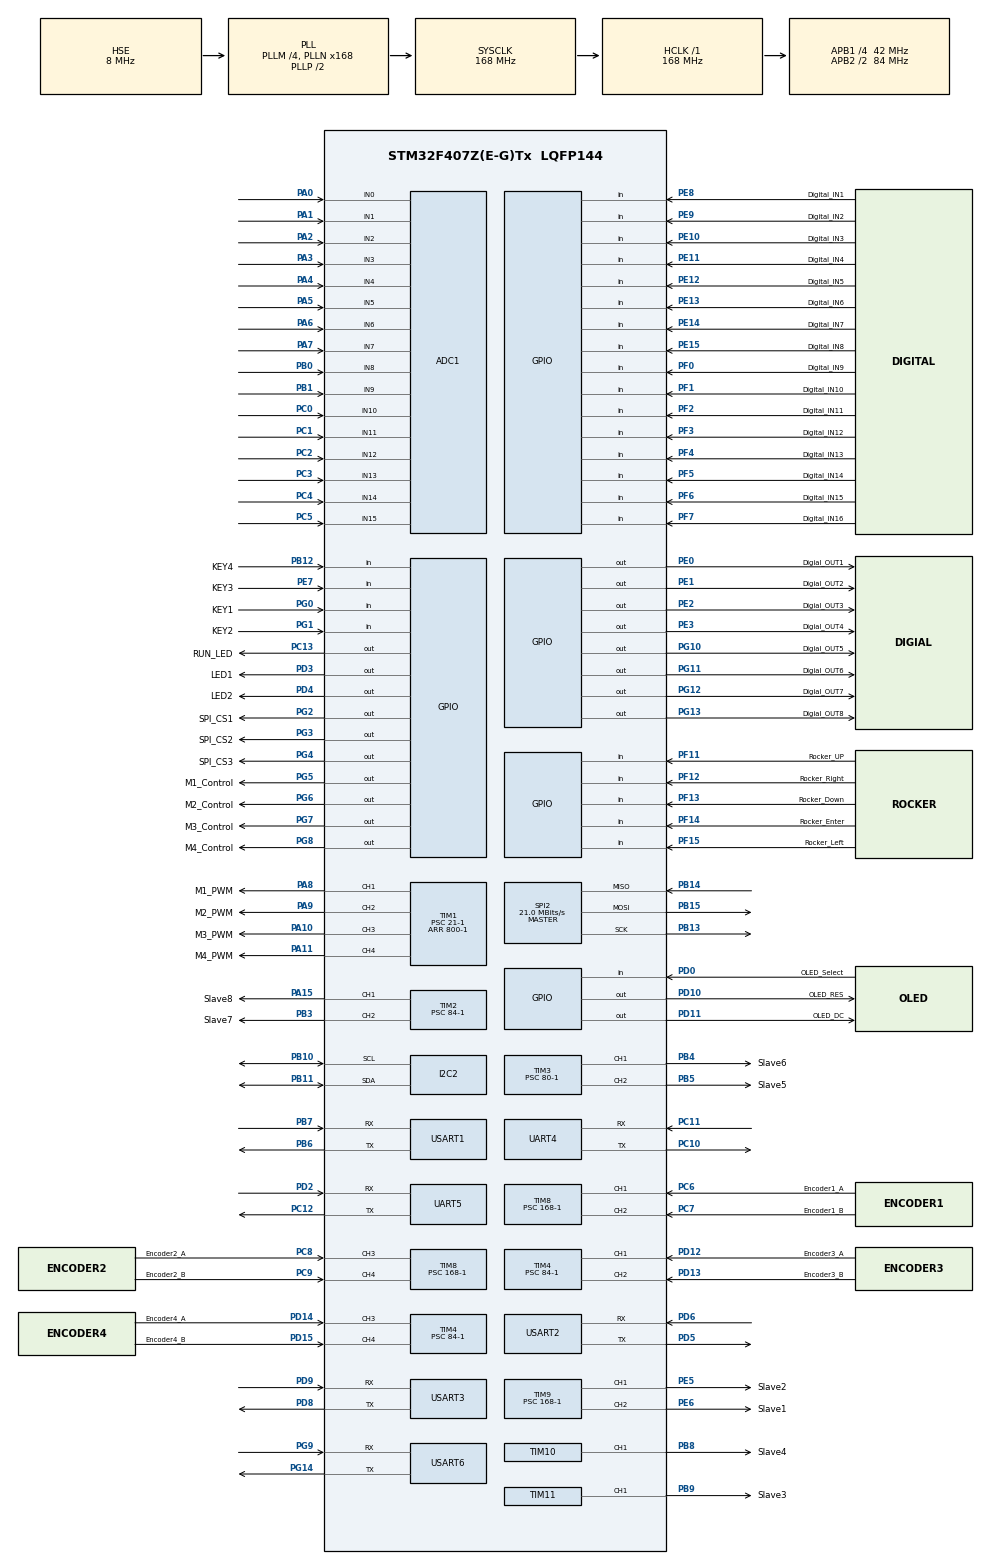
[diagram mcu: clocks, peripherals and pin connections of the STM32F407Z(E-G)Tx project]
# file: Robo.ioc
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ADC1.Channel-1\#ChannelRegularConversion=ADC_CHANNEL_0
ADC1.Channel-2\#ChannelRegularConversion=ADC_CHANNEL_2
ADC1.Channel-3\#ChannelRegularConversion=ADC_CHANNEL_4
ADC1.Channel-4\#ChannelRegularConversion=ADC_CHANNEL_6
ADC1.Channel-5\#ChannelRegularConversion=ADC_CHANNEL_8
ADC1.Channel-6\#ChannelRegularConversion=ADC_CHANNEL_10
ADC1.Channel-7\#ChannelRegularConversion=ADC_CHANNEL_12
ADC1.Channel-8\#ChannelRegularConversion=ADC_CHANNEL_14
ADC1.ClockPrescaler=ADC_CLOCK_SYNC_PCLK_DIV8
ADC1.DMAContinuousRequests=ENABLE
ADC1.ExternalTrigConv=ADC_EXTERNALTRIGCONV_T5_CC1
ADC1.Mode=ADC_DUALMODE_REGSIMULT
ADC1.NbrOfConversion=8
ADC1.NbrOfConversionFlag=1
ADC1.Rank-1\#ChannelRegularConversion=1
ADC1.Rank-2\#ChannelRegularConversion=2
ADC1.Rank-3\#ChannelRegularConversion=3
ADC1.Rank-4\#ChannelRegularConversion=4
ADC1.Rank-5\#ChannelRegularConversion=5
ADC1.Rank-6\#ChannelRegularConversion=6
ADC1.Rank-7\#ChannelRegularConversion=7
ADC1.Rank-8\#ChannelRegularConversion=8
ADC1.SamplingTime-1\#ChannelRegularConversion=ADC_SAMPLETIME_56CYCLES
ADC1.SamplingTime-2\#ChannelRegularConversion=ADC_SAMPLETIME_56CYCLES
ADC1.SamplingTime-3\#ChannelRegularConversion=ADC_SAMPLETIME_56CYCLES
ADC1.SamplingTime-4\#ChannelRegularConversion=ADC_SAMPLETIME_56CYCLES
ADC1.SamplingTime-5\#ChannelRegularConversion=ADC_SAMPLETIME_56CYCLES
ADC1.SamplingTime-6\#ChannelRegularConversion=ADC_SAMPLETIME_56CYCLES
ADC1.SamplingTime-7\#ChannelRegularConversion=ADC_SAMPLETIME_56CYCLES
ADC1.SamplingTime-8\#ChannelRegularConversion=ADC_SAMPLETIME_56CYCLES
ADC1.master=1
ADC2.Channel-0\#ChannelRegularConversion=ADC_CHANNEL_1
ADC2.Channel-1\#ChannelRegularConversion=ADC_CHANNEL_3
ADC2.Channel-2\#ChannelRegularConversion=ADC_CHANNEL_5
ADC2.Channel-3\#ChannelRegularConversion=ADC_CHANNEL_7
ADC2.Channel-4\#ChannelRegularConversion=ADC_CHANNEL_9
ADC2.Channel-5\#ChannelRegularConversion=ADC_CHANNEL_11
ADC2.Channel-6\#ChannelRegularConversion=ADC_CHANNEL_13
ADC2.Channel-7\#ChannelRegularConversion=ADC_CHANNEL_15
ADC2.ClockPrescaler=ADC_CLOCK_SYNC_PCLK_DIV8
ADC2.DMAAccessMode=ADC_DMAACCESSMODE_2
ADC2.Mode=ADC_DUALMODE_REGSIMULT
ADC2.NbrOfConversion=8
ADC2.NbrOfConversionFlag=1
ADC2.Rank-0\#ChannelRegularConversion=1
ADC2.Rank-1\#ChannelRegularConversion=2
ADC2.Rank-2\#ChannelRegularConversion=3
ADC2.Rank-3\#ChannelRegularConversion=4
ADC2.Rank-4\#ChannelRegularConversion=5
ADC2.Rank-5\#ChannelRegularConversion=6
ADC2.Rank-6\#ChannelRegularConversion=7
ADC2.Rank-7\#ChannelRegularConversion=8
ADC2.SamplingTime-0\#ChannelRegularConversion=ADC_SAMPLETIME_56CYCLES
ADC2.SamplingTime-1\#ChannelRegularConversion=ADC_SAMPLETIME_56CYCLES
ADC2.SamplingTime-2\#ChannelRegularConversion=ADC_SAMPLETIME_56CYCLES
ADC2.SamplingTime-3\#ChannelRegularConversion=ADC_SAMPLETIME_56CYCLES
ADC2.SamplingTime-4\#ChannelRegularConversion=ADC_SAMPLETIME_56CYCLES
ADC2.SamplingTime-5\#ChannelRegularConversion=ADC_SAMPLETIME_56CYCLES
ADC2.SamplingTime-6\#ChannelRegularConversion=ADC_SAMPLETIME_56CYCLES
ADC2.SamplingTime-7\#ChannelRegularConversion=ADC_SAMPLETIME_56CYCLES
Dma.ADC1.0.Direction=DMA_PERIPH_TO_MEMORY
Dma.ADC1.0.FIFOMode=DMA_FIFOMODE_DISABLE
Dma.ADC1.0.Instance=DMA2_Stream0
Dma.ADC1.0.MemDataAlignment=DMA_MDATAALIGN_WORD
Dma.ADC1.0.MemInc=DMA_MINC_ENABLE
Dma.ADC1.0.Mode=DMA_CIRCULAR
Dma.ADC1.0.PeriphDataAlignment=DMA_PDATAALIGN_WORD
Dma.ADC1.0.PeriphInc=DMA_PINC_DISABLE
Dma.ADC1.0.Priority=DMA_PRIORITY_MEDIUM
Dma.Request0=ADC1
Dma.Request1=TIM4_CH1
Dma.Request2=TIM8_CH1
Dma.Request3=TIM8_CH2
Dma.Request4=TIM8_CH3
Dma.Request5=TIM8_CH4/TRIG/COM
Dma.Request6=TIM4_CH2
Dma.Request7=TIM4_CH3
Dma.Request8=USART3_TX
Dma.Request9=USART3_RX
Dma.TIM4_CH1.1.Direction=DMA_PERIPH_TO_MEMORY
Dma.TIM4_CH1.1.FIFOMode=DMA_FIFOMODE_DISABLE
Dma.TIM4_CH1.1.Instance=DMA1_Stream0
Dma.TIM4_CH1.1.MemDataAlignment=DMA_MDATAALIGN_HALFWORD
Dma.TIM4_CH1.1.MemInc=DMA_MINC_DISABLE
Dma.TIM4_CH1.1.Mode=DMA_CIRCULAR
Dma.TIM4_CH1.1.PeriphDataAlignment=DMA_PDATAALIGN_HALFWORD
Dma.TIM4_CH1.1.PeriphInc=DMA_PINC_DISABLE
Dma.TIM4_CH1.1.Priority=DMA_PRIORITY_HIGH
Dma.TIM4_CH2.6.Direction=DMA_PERIPH_TO_MEMORY
Dma.TIM4_CH2.6.FIFOMode=DMA_FIFOMODE_DISABLE
Dma.TIM4_CH2.6.Instance=DMA1_Stream3
Dma.TIM4_CH2.6.MemDataAlignment=DMA_MDATAALIGN_HALFWORD
Dma.TIM4_CH2.6.MemInc=DMA_MINC_DISABLE
Dma.TIM4_CH2.6.Mode=DMA_CIRCULAR
Dma.TIM4_CH2.6.PeriphDataAlignment=DMA_PDATAALIGN_HALFWORD
Dma.TIM4_CH2.6.PeriphInc=DMA_PINC_DISABLE
Dma.TIM4_CH2.6.Priority=DMA_PRIORITY_HIGH
Dma.TIM4_CH3.7.Direction=DMA_PERIPH_TO_MEMORY
Dma.TIM4_CH3.7.FIFOMode=DMA_FIFOMODE_DISABLE
Dma.TIM4_CH3.7.Instance=DMA1_Stream7
Dma.TIM4_CH3.7.MemDataAlignment=DMA_MDATAALIGN_HALFWORD
Dma.TIM4_CH3.7.MemInc=DMA_MINC_DISABLE
Dma.TIM4_CH3.7.Mode=DMA_CIRCULAR
Dma.TIM4_CH3.7.PeriphDataAlignment=DMA_PDATAALIGN_HALFWORD
Dma.TIM4_CH3.7.PeriphInc=DMA_PINC_DISABLE
Dma.TIM4_CH3.7.Priority=DMA_PRIORITY_HIGH
Dma.TIM8_CH1.2.Direction=DMA_PERIPH_TO_MEMORY
Dma.TIM8_CH1.2.FIFOMode=DMA_FIFOMODE_DISABLE
Dma.TIM8_CH1.2.Instance=DMA2_Stream2
Dma.TIM8_CH1.2.MemDataAlignment=DMA_MDATAALIGN_HALFWORD
Dma.TIM8_CH1.2.MemInc=DMA_MINC_DISABLE
Dma.TIM8_CH1.2.Mode=DMA_CIRCULAR
Dma.TIM8_CH1.2.PeriphDataAlignment=DMA_PDATAALIGN_HALFWORD
Dma.TIM8_CH1.2.PeriphInc=DMA_PINC_DISABLE
Dma.TIM8_CH1.2.Priority=DMA_PRIORITY_HIGH
Dma.TIM8_CH2.3.Direction=DMA_PERIPH_TO_MEMORY
Dma.TIM8_CH2.3.FIFOMode=DMA_FIFOMODE_DISABLE
Dma.TIM8_CH2.3.Instance=DMA2_Stream3
Dma.TIM8_CH2.3.MemDataAlignment=DMA_MDATAALIGN_HALFWORD
Dma.TIM8_CH2.3.MemInc=DMA_MINC_DISABLE
Dma.TIM8_CH2.3.Mode=DMA_CIRCULAR
Dma.TIM8_CH2.3.PeriphDataAlignment=DMA_PDATAALIGN_HALFWORD
Dma.TIM8_CH2.3.PeriphInc=DMA_PINC_DISABLE
Dma.TIM8_CH2.3.Priority=DMA_PRIORITY_HIGH
Dma.TIM8_CH3.4.Direction=DMA_PERIPH_TO_MEMORY
Dma.TIM8_CH3.4.FIFOMode=DMA_FIFOMODE_DISABLE
Dma.TIM8_CH3.4.Instance=DMA2_Stream4
Dma.TIM8_CH3.4.MemDataAlignment=DMA_MDATAALIGN_HALFWORD
Dma.TIM8_CH3.4.MemInc=DMA_MINC_DISABLE
Dma.TIM8_CH3.4.Mode=DMA_CIRCULAR
Dma.TIM8_CH3.4.PeriphDataAlignment=DMA_PDATAALIGN_HALFWORD
Dma.TIM8_CH3.4.PeriphInc=DMA_PINC_DISABLE
Dma.TIM8_CH3.4.Priority=DMA_PRIORITY_HIGH
Dma.TIM8_CH4/TRIG/COM.5.Direction=DMA_PERIPH_TO_MEMORY
Dma.TIM8_CH4/TRIG/COM.5.FIFOMode=DMA_FIFOMODE_DISABLE
Dma.TIM8_CH4/TRIG/COM.5.Instance=DMA2_Stream7
Dma.TIM8_CH4/TRIG/COM.5.MemDataAlignment=DMA_MDATAALIGN_HALFWORD
Dma.TIM8_CH4/TRIG/COM.5.MemInc=DMA_MINC_DISABLE
Dma.TIM8_CH4/TRIG/COM.5.Mode=DMA_CIRCULAR
Dma.TIM8_CH4/TRIG/COM.5.PeriphDataAlignment=DMA_PDATAALIGN_HALFWORD
Dma.TIM8_CH4/TRIG/COM.5.PeriphInc=DMA_PINC_DISABLE
Dma.TIM8_CH4/TRIG/COM.5.Priority=DMA_PRIORITY_HIGH
Dma.USART3_RX.9.Direction=DMA_PERIPH_TO_MEMORY
Dma.USART3_RX.9.FIFOMode=DMA_FIFOMODE_DISABLE
Dma.USART3_RX.9.Instance=DMA1_Stream1
Dma.USART3_RX.9.MemDataAlignment=DMA_MDATAALIGN_BYTE
Dma.USART3_RX.9.MemInc=DMA_MINC_ENABLE
Dma.USART3_RX.9.Mode=DMA_CIRCULAR
Dma.USART3_RX.9.PeriphDataAlignment=DMA_PDATAALIGN_BYTE
Dma.USART3_RX.9.PeriphInc=DMA_PINC_DISABLE
Dma.USART3_RX.9.Priority=DMA_PRIORITY_LOW
Dma.USART3_TX.8.Direction=DMA_MEMORY_TO_PERIPH
Dma.USART3_TX.8.FIFOMode=DMA_FIFOMODE_DISABLE
Dma.USART3_TX.8.Instance=DMA1_Stream4
Dma.USART3_TX.8.MemDataAlignment=DMA_MDATAALIGN_BYTE
Dma.USART3_TX.8.MemInc=DMA_MINC_ENABLE
Dma.USART3_TX.8.Mode=DMA_NORMAL
Dma.USART3_TX.8.PeriphDataAlignment=DMA_PDATAALIGN_BYTE
Dma.USART3_TX.8.PeriphInc=DMA_PINC_DISABLE
Dma.USART3_TX.8.Priority=DMA_PRIORITY_LOW
FREERTOS.INCLUDE_uxTaskGetStackHighWaterMark2=1
FREERTOS.INCLUDE_xTaskGetHandle=1
FREERTOS.Tasks01=defaultTask,24,64,StartDefaultTask,Default,NULL,Dynamic,NULL,NULL;RUN_LED_Flash,8,64,RUN_LED_Flash_Task,As weak,NULL,Dynamic,NULL,NULL;State_LED_Flash,8,64,State_LED_Flash_Task,As weak,NULL,Dynamic,NULL,NULL;KEY_Scan,40,64,KEY_Scan_Task,As weak,NULL,Dynamic,NULL,NULL;Set_And_Show,24,512,Set_And_Show_Task,As weak,NULL,Dynamic,NULL,NULL;Slow_Compute,32,512,Slow_Compute_Task,As weak,NULL,Dynamic,NULL,NULL;UART_Debug,16,512,UART_Debug_Task,As weak,NULL,Dynamic,NULL,NULL;High_Compute,32,512,High_Compute_Task,As weak,NULL,Dynamic,NULL,NULL
FREERTOS.configENABLE_FPU=1
FREERTOS.configMINIMAL_STACK_SIZE=64
FREERTOS.configTICK_RATE_HZ=1000
I2C2.I2C_Mode=I2C_Standard
Mcu.Family=STM32F4
Mcu.Name=STM32F407Z(E-G)Tx
Mcu.Package=LQFP144
NVIC.DMA1_Stream0_IRQn=true\:5\:0\:false\:false\:true\:true\:false\:true\:true
NVIC.DMA1_Stream1_IRQn=true\:5\:0\:false\:false\:true\:true\:false\:true\:true
NVIC.DMA1_Stream3_IRQn=true\:5\:0\:false\:false\:true\:true\:false\:true\:true
NVIC.DMA1_Stream4_IRQn=true\:5\:0\:false\:false\:true\:true\:false\:true\:true
NVIC.DMA1_Stream7_IRQn=true\:5\:0\:false\:false\:true\:true\:false\:true\:true
NVIC.DMA2_Stream0_IRQn=true\:5\:0\:false\:false\:true\:true\:false\:true\:true
NVIC.DMA2_Stream2_IRQn=true\:5\:0\:false\:false\:true\:true\:false\:true\:true
NVIC.DMA2_Stream3_IRQn=true\:5\:0\:false\:false\:true\:true\:false\:true\:true
NVIC.DMA2_Stream4_IRQn=true\:5\:0\:false\:false\:true\:true\:false\:true\:true
NVIC.DMA2_Stream7_IRQn=true\:5\:0\:false\:false\:true\:true\:false\:true\:true
NVIC.PriorityGroup=NVIC_PRIORITYGROUP_4
NVIC.SPI2_IRQn=true\:5\:0\:false\:false\:true\:true\:true\:true\:true
NVIC.TIM4_IRQn=true\:0\:0\:true\:false\:true\:false\:true\:true\:true
NVIC.TIM7_IRQn=true\:15\:0\:false\:false\:true\:false\:false\:true\:true
NVIC.TimeBase=TIM7_IRQn
NVIC.TimeBaseIP=TIM7
NVIC.USART3_IRQn=true\:5\:0\:false\:false\:true\:true\:true\:true\:true
PA0-WKUP.Signal=ADCx_IN0
PA1.Signal=ADCx_IN1
PA10.GPIO_Label=M3_PWM
PA10.Signal=S_TIM1_CH3
PA11.GPIO_Label=M4_PWM
PA11.Signal=S_TIM1_CH4
PA13.Mode=Serial_Wire
PA13.Signal=SYS_JTMS-SWDIO
PA14.Mode=Serial_Wire
PA14.Signal=SYS_JTCK-SWCLK
PA15.GPIO_Label=Slave8
PA15.Signal=S_TIM2_CH1_ETR
PA2.Signal=ADCx_IN2
PA3.Signal=ADCx_IN3
PA4.Signal=ADCx_IN4
PA5.Signal=ADCx_IN5
PA6.Signal=ADCx_IN6
PA7.Signal=ADCx_IN7
PA8.GPIO_Label=M1_PWM
PA8.Signal=S_TIM1_CH1
PA9.GPIO_Label=M2_PWM
PA9.Signal=S_TIM1_CH2
PB0.Signal=ADCx_IN8
PB1.Signal=ADCx_IN9
PB10.Mode=I2C
PB10.Signal=I2C2_SCL
PB11.Mode=I2C
PB11.Signal=I2C2_SDA
PB12.GPIO_Label=KEY4
PB12.GPIO_PuPd=GPIO_PULLUP
PB12.Signal=GPIO_Input
PB13.Mode=Full_Duplex_Master
PB13.Signal=SPI2_SCK
PB14.Mode=Full_Duplex_Master
PB14.Signal=SPI2_MISO
PB15.Mode=Full_Duplex_Master
PB15.Signal=SPI2_MOSI
PB3.GPIO_Label=Slave7
PB3.Signal=S_TIM2_CH2
PB4.GPIO_Label=Slave6
PB4.Signal=S_TIM3_CH1
PB5.GPIO_Label=Slave5
PB5.Signal=S_TIM3_CH2
PB6.Mode=Asynchronous
PB6.Signal=USART1_TX
PB7.Mode=Asynchronous
PB7.Signal=USART1_RX
PB8.GPIO_Label=Slave4
PB8.Signal=S_TIM10_CH1
PB9.GPIO_Label=Slave3
PB9.Signal=S_TIM11_CH1
PC0.Signal=ADCx_IN10
PC1.Signal=ADCx_IN11
PC10.Mode=Asynchronous
PC10.Signal=UART4_TX
PC11.Mode=Asynchronous
PC11.Signal=UART4_RX
PC12.Mode=Asynchronous
PC12.Signal=UART5_TX
PC13-ANTI_TAMP.GPIO_Label=RUN_LED
PC13-ANTI_TAMP.PinState=GPIO_PIN_SET
PC13-ANTI_TAMP.Signal=GPIO_Output
PC14-OSC32_IN.Mode=LSE-External-Oscillator
PC14-OSC32_IN.Signal=RCC_OSC32_IN
PC15-OSC32_OUT.Mode=LSE-External-Oscillator
PC15-OSC32_OUT.Signal=RCC_OSC32_OUT
PC2.Signal=ADCx_IN12
PC3.Signal=ADCx_IN13
PC4.Signal=ADCx_IN14
PC5.Signal=ADCx_IN15
PC6.GPIO_Label=Encoder1_A
PC6.GPIO_PuPd=GPIO_PULLUP
PC6.Signal=S_TIM8_CH1
PC7.GPIO_Label=Encoder1_B
PC7.GPIO_PuPd=GPIO_PULLUP
PC7.Signal=S_TIM8_CH2
PC8.GPIO_Label=Encoder2_A
PC8.GPIO_PuPd=GPIO_PULLUP
PC8.Signal=S_TIM8_CH3
PC9.GPIO_Label=Encoder2_B
PC9.GPIO_PuPd=GPIO_PULLUP
PC9.Signal=S_TIM8_CH4
PD0.GPIO_Label=OLED_Select
PD0.Signal=GPIO_Input
PD10.GPIO_Label=OLED_RES
PD10.GPIO_Speed=GPIO_SPEED_FREQ_VERY_HIGH
PD10.PinState=GPIO_PIN_SET
PD10.Signal=GPIO_Output
PD11.GPIO_Label=OLED_DC
PD11.GPIO_Speed=GPIO_SPEED_FREQ_VERY_HIGH
PD11.PinState=GPIO_PIN_SET
PD11.Signal=GPIO_Output
PD12.GPIO_Label=Encoder3_A
PD12.GPIO_PuPd=GPIO_PULLUP
PD12.Signal=S_TIM4_CH1
PD13.GPIO_Label=Encoder3_B
PD13.GPIO_PuPd=GPIO_PULLUP
PD13.Signal=S_TIM4_CH2
PD14.GPIO_Label=Encoder4_A
PD14.GPIO_PuPd=GPIO_PULLUP
PD14.Signal=S_TIM4_CH3
PD15.GPIO_Label=Encoder4_B
PD15.GPIO_PuPd=GPIO_PULLUP
PD15.Signal=S_TIM4_CH4
PD2.Mode=Asynchronous
PD2.Signal=UART5_RX
PD3.GPIO_Label=LED1
PD3.Signal=GPIO_Output
PD4.GPIO_Label=LED2
PD4.Signal=GPIO_Output
PD5.Mode=Asynchronous
PD5.Signal=USART2_TX
PD6.Mode=Asynchronous
PD6.Signal=USART2_RX
PD8.Mode=Asynchronous
PD8.Signal=USART3_TX
PD9.Mode=Asynchronous
PD9.Signal=USART3_RX
PE0.GPIO_Label=Digial_OUT1
PE0.Signal=GPIO_Output
PE1.GPIO_Label=Digial_OUT2
PE1.Signal=GPIO_Output
PE10.GPIO_Label=Digital_IN3
PE10.Signal=GPIO_Input
PE11.GPIO_Label=Digital_IN4
PE11.Signal=GPIO_Input
PE12.GPIO_Label=Digital_IN5
PE12.Signal=GPIO_Input
PE13.GPIO_Label=Digital_IN6
PE13.Signal=GPIO_Input
PE14.GPIO_Label=Digital_IN7
PE14.Signal=GPIO_Input
PE15.GPIO_Label=Digital_IN8
PE15.Signal=GPIO_Input
PE2.GPIO_Label=Digial_OUT3
PE2.Signal=GPIO_Output
PE3.GPIO_Label=Digial_OUT4
PE3.Signal=GPIO_Output
PE5.GPIO_Label=Slave2
PE5.Signal=S_TIM9_CH1
PE6.GPIO_Label=Slave1
PE6.Signal=S_TIM9_CH2
PE7.GPIO_Label=KEY3
PE7.GPIO_PuPd=GPIO_PULLUP
PE7.Signal=GPIO_Input
PE8.GPIO_Label=Digital_IN1
PE8.Signal=GPIO_Input
PE9.GPIO_Label=Digital_IN2
PE9.Signal=GPIO_Input
PF0.GPIO_Label=Digital_IN9
PF0.Signal=GPIO_Input
PF1.GPIO_Label=Digital_IN10
PF1.Signal=GPIO_Input
PF11.GPIO_Label=Rocker_UP
PF11.GPIO_PuPd=GPIO_PULLUP
PF11.Signal=GPIO_Input
PF12.GPIO_Label=Rocker_Right
PF12.GPIO_PuPd=GPIO_PULLUP
PF12.Signal=GPIO_Input
PF13.GPIO_Label=Rocker_Down
PF13.GPIO_PuPd=GPIO_PULLUP
PF13.Signal=GPIO_Input
PF14.GPIO_Label=Rocker_Enter
PF14.GPIO_PuPd=GPIO_PULLUP
PF14.Signal=GPIO_Input
PF15.GPIO_Label=Rocker_Left
PF15.GPIO_PuPd=GPIO_PULLUP
PF15.Signal=GPIO_Input
PF2.GPIO_Label=Digital_IN11
PF2.Signal=GPIO_Input
PF3.GPIO_Label=Digital_IN12
PF3.Signal=GPIO_Input
PF4.GPIO_Label=Digital_IN13
PF4.Signal=GPIO_Input
PF5.GPIO_Label=Digital_IN14
PF5.Signal=GPIO_Input
PF6.GPIO_Label=Digital_IN15
PF6.Signal=GPIO_Input
PF7.GPIO_Label=Digital_IN16
PF7.Signal=GPIO_Input
PG0.GPIO_Label=KEY1
PG0.GPIO_PuPd=GPIO_PULLUP
PG0.Signal=GPIO_Input
PG1.GPIO_Label=KEY2
PG1.GPIO_PuPd=GPIO_PULLUP
PG1.Signal=GPIO_Input
PG10.GPIO_Label=Digial_OUT5
PG10.Signal=GPIO_Output
PG11.GPIO_Label=Digial_OUT6
PG11.Signal=GPIO_Output
PG12.GPIO_Label=Digial_OUT7
PG12.Signal=GPIO_Output
PG13.GPIO_Label=Digial_OUT8
PG13.Signal=GPIO_Output
PG14.Mode=Asynchronous
PG14.Signal=USART6_TX
PG2.GPIO_Label=SPI_CS1
PG2.GPIO_Speed=GPIO_SPEED_FREQ_VERY_HIGH
PG2.PinState=GPIO_PIN_SET
PG2.Signal=GPIO_Output
PG3.GPIO_Label=SPI_CS2
PG3.GPIO_Speed=GPIO_SPEED_FREQ_VERY_HIGH
PG3.PinState=GPIO_PIN_SET
PG3.Signal=GPIO_Output
PG4.GPIO_Label=SPI_CS3
PG4.GPIO_Speed=GPIO_SPEED_FREQ_VERY_HIGH
PG4.PinState=GPIO_PIN_SET
PG4.Signal=GPIO_Output
PG5.GPIO_Label=M1_Control
PG5.Signal=GPIO_Output
PG6.GPIO_Label=M2_Control
PG6.Signal=GPIO_Output
PG7.GPIO_Label=M3_Control
PG7.Signal=GPIO_Output
PG8.GPIO_Label=M4_Control
PG8.Signal=GPIO_Output
PG9.Mode=Asynchronous
PG9.Signal=USART6_RX
PH0-OSC_IN.Mode=HSE-External-Oscillator
PH0-OSC_IN.Signal=RCC_OSC_IN
PH1-OSC_OUT.Mode=HSE-External-Oscillator
PH1-OSC_OUT.Signal=RCC_OSC_OUT
ProjectManager.HeapSize=0x200
ProjectManager.StackSize=0x400
ProjectManager.TargetToolchain=MDK-ARM V5.32
RCC.48MHZClocksFreq_Value=84000000
RCC.AHBFreq_Value=168000000
RCC.APB1CLKDivider=RCC_HCLK_DIV4
RCC.APB1Freq_Value=42000000
RCC.APB1TimFreq_Value=84000000
RCC.APB2CLKDivider=RCC_HCLK_DIV2
RCC.APB2Freq_Value=84000000
RCC.APB2TimFreq_Value=168000000
RCC.CortexFreq_Value=168000000
RCC.HCLKFreq_Value=168000000
RCC.HSE_VALUE=8000000
RCC.HSI_VALUE=16000000
RCC.PLLM=4
RCC.PLLN=168
RCC.PLLSourceVirtual=RCC_PLLSOURCE_HSE
RCC.SYSCLKFreq_VALUE=168000000
RCC.SYSCLKSource=RCC_SYSCLKSOURCE_PLLCLK
RCC.VCOOutputFreq_Value=336000000
SH.ADCx_IN0.0=ADC1_IN0,IN0
SH.ADCx_IN0.1=ADC2_IN0,IN0
SH.ADCx_IN1.0=ADC1_IN1,IN1
SH.ADCx_IN1.1=ADC2_IN1,IN1
SH.ADCx_IN10.0=ADC1_IN10,IN10
SH.ADCx_IN10.1=ADC2_IN10,IN10
SH.ADCx_IN11.0=ADC1_IN11,IN11
SH.ADCx_IN11.1=ADC2_IN11,IN11
SH.ADCx_IN12.0=ADC1_IN12,IN12
SH.ADCx_IN12.1=ADC2_IN12,IN12
SH.ADCx_IN13.0=ADC1_IN13,IN13
SH.ADCx_IN13.1=ADC2_IN13,IN13
SH.ADCx_IN14.0=ADC1_IN14,IN14
SH.ADCx_IN14.1=ADC2_IN14,IN14
SH.ADCx_IN15.0=ADC1_IN15,IN15
SH.ADCx_IN15.1=ADC2_IN15,IN15
SH.ADCx_IN2.0=ADC1_IN2,IN2
SH.ADCx_IN2.1=ADC2_IN2,IN2
SH.ADCx_IN3.0=ADC1_IN3,IN3
SH.ADCx_IN3.1=ADC2_IN3,IN3
SH.ADCx_IN4.0=ADC1_IN4,IN4
SH.ADCx_IN4.1=ADC2_IN4,IN4
SH.ADCx_IN5.0=ADC1_IN5,IN5
SH.ADCx_IN5.1=ADC2_IN5,IN5
SH.ADCx_IN6.0=ADC1_IN6,IN6
SH.ADCx_IN6.1=ADC2_IN6,IN6
SH.ADCx_IN7.0=ADC1_IN7,IN7
SH.ADCx_IN7.1=ADC2_IN7,IN7
SH.ADCx_IN8.0=ADC1_IN8,IN8
SH.ADCx_IN8.1=ADC2_IN8,IN8
SH.ADCx_IN9.0=ADC1_IN9,IN9
SH.ADCx_IN9.1=ADC2_IN9,IN9
SH.S_TIM10_CH1.0=TIM10_CH1,PWM Generation1 CH1
SH.S_TIM11_CH1.0=TIM11_CH1,PWM Generation1 CH1
SH.S_TIM1_CH1.0=TIM1_CH1,PWM Generation1 CH1
SH.S_TIM1_CH2.0=TIM1_CH2,PWM Generation2 CH2
SH.S_TIM1_CH3.0=TIM1_CH3,PWM Generation3 CH3
SH.S_TIM1_CH4.0=TIM1_CH4,PWM Generation4 CH4
SH.S_TIM2_CH1_ETR.0=TIM2_CH1,PWM Generation1 CH1
SH.S_TIM2_CH2.0=TIM2_CH2,PWM Generation2 CH2
SH.S_TIM3_CH1.0=TIM3_CH1,PWM Generation1 CH1
SH.S_TIM3_CH2.0=TIM3_CH2,PWM Generation2 CH2
SH.S_TIM4_CH1.0=TIM4_CH1,Input_Capture1_from_TI1
SH.S_TIM4_CH2.0=TIM4_CH2,Input_Capture2_from_TI2
SH.S_TIM4_CH3.0=TIM4_CH3,Input_Capture3_from_TI3
SH.S_TIM4_CH4.0=TIM4_CH4,Input_Capture4_from_TI4
SH.S_TIM8_CH1.0=TIM8_CH1,Input_Capture1_from_TI1
SH.S_TIM8_CH2.0=TIM8_CH2,Input_Capture2_from_TI2
SH.S_TIM8_CH3.0=TIM8_CH3,Input_Capture3_from_TI3
SH.S_TIM8_CH4.0=TIM8_CH4,Input_Capture4_from_TI4
SH.S_TIM9_CH1.0=TIM9_CH1,PWM Generation1 CH1
SH.S_TIM9_CH2.0=TIM9_CH2,PWM Generation2 CH2
SPI2.BaudRatePrescaler=SPI_BAUDRATEPRESCALER_2
SPI2.CalculateBaudRate=21.0 MBits/s
SPI2.Direction=SPI_DIRECTION_2LINES
SPI2.Mode=SPI_MODE_MASTER
SPI2.VirtualType=VM_MASTER
TIM1.Channel-PWM\ Generation1\ CH1=TIM_CHANNEL_1
TIM1.Channel-PWM\ Generation2\ CH2=TIM_CHANNEL_2
TIM1.Channel-PWM\ Generation3\ CH3=TIM_CHANNEL_3
TIM1.Channel-PWM\ Generation4\ CH4=TIM_CHANNEL_4
TIM1.Period=800-1
TIM1.Prescaler=21-1
TIM10.Channel=TIM_CHANNEL_1
TIM10.Period=20000-1
TIM10.Prescaler=168-1
TIM11.Channel=TIM_CHANNEL_1
TIM11.Period=20000-1
TIM11.Prescaler=168-1
TIM12.Period=50-1
TIM12.Prescaler=84-1
TIM2.Channel-PWM\ Generation1\ CH1=TIM_CHANNEL_1
TIM2.Channel-PWM\ Generation2\ CH2=TIM_CHANNEL_2
TIM2.Period=20000-1
TIM2.Prescaler=84-1
TIM3.Channel-PWM\ Generation1\ CH1=TIM_CHANNEL_1
TIM3.Channel-PWM\ Generation2\ CH2=TIM_CHANNEL_2
TIM3.Period=20000-1
TIM3.Prescaler=80-1
TIM4.Channel-Input_Capture1_from_TI1=TIM_CHANNEL_1
TIM4.Channel-Input_Capture2_from_TI2=TIM_CHANNEL_2
TIM4.Channel-Input_Capture3_from_TI3=TIM_CHANNEL_3
TIM4.Channel-Input_Capture4_from_TI4=TIM_CHANNEL_4
TIM4.ICPolarity_CH1=TIM_INPUTCHANNELPOLARITY_BOTHEDGE
TIM4.ICPolarity_CH2=TIM_INPUTCHANNELPOLARITY_BOTHEDGE
TIM4.ICPolarity_CH3=TIM_INPUTCHANNELPOLARITY_BOTHEDGE
TIM4.ICPolarity_CH4=TIM_INPUTCHANNELPOLARITY_BOTHEDGE
TIM4.Period=65535
TIM4.Prescaler=84-1
TIM5.Channel-PWM\ Generation1\ No\ Output=TIM_CHANNEL_1
TIM5.OCMode_PWM-PWM\ Generation1\ No\ Output=TIM_OCMODE_PWM1
TIM5.Period=500-1
TIM5.Prescaler=84-1
TIM5.Pulse-PWM\ Generation1\ No\ Output=250
TIM5.TIM_MasterOutputTrigger=TIM_TRGO_OC1REF
TIM5.TIM_MasterSlaveMode=TIM_MASTERSLAVEMODE_ENABLE
TIM6.AutoReloadPreload=TIM_AUTORELOAD_PRELOAD_DISABLE
TIM6.Period=1000-1
TIM6.Prescaler=84-1
TIM8.Channel-Input_Capture1_from_TI1=TIM_CHANNEL_1
TIM8.Channel-Input_Capture2_from_TI2=TIM_CHANNEL_2
TIM8.Channel-Input_Capture3_from_TI3=TIM_CHANNEL_3
TIM8.Channel-Input_Capture4_from_TI4=TIM_CHANNEL_4
TIM8.ICPolarity_CH1=TIM_INPUTCHANNELPOLARITY_BOTHEDGE
TIM8.ICPolarity_CH2=TIM_INPUTCHANNELPOLARITY_BOTHEDGE
TIM8.ICPolarity_CH3=TIM_INPUTCHANNELPOLARITY_BOTHEDGE
TIM8.ICPolarity_CH4=TIM_INPUTCHANNELPOLARITY_BOTHEDGE
TIM8.Period=65535
TIM8.Prescaler=168-1
TIM9.Channel-PWM\ Generation1\ CH1=TIM_CHANNEL_1
TIM9.Channel-PWM\ Generation2\ CH2=TIM_CHANNEL_2
TIM9.Period=20000-1
TIM9.Prescaler=168-1
UART4.VirtualMode=Asynchronous
UART5.VirtualMode=Asynchronous
USART1.VirtualMode=VM_ASYNC
USART2.VirtualMode=VM_ASYNC
USART3.VirtualMode=VM_ASYNC
USART6.VirtualMode=VM_ASYNC
VP_FREERTOS_VS_CMSIS_V2.Mode=CMSIS_V2
VP_SYS_VS_tim7.Mode=TIM7
VP_TIM10_VS_ClockSourceINT.Mode=Enable_Timer
VP_TIM11_VS_ClockSourceINT.Mode=Enable_Timer
VP_TIM12_VS_ClockSourceINT.Mode=Internal
VP_TIM2_VS_ClockSourceINT.Mode=Internal
VP_TIM3_VS_ClockSourceINT.Mode=Internal
VP_TIM4_VS_ClockSourceINT.Mode=Internal
VP_TIM5_VS_ClockSourceINT.Mode=Internal
VP_TIM5_VS_no_output1.Mode=PWM Generation1 No Output
VP_TIM6_VS_ClockSourceINT.Mode=Enable_Timer
VP_TIM8_VS_ClockSourceINT.Mode=Internal
VP_TIM9_VS_ClockSourceINT.Mode=Internal
board=custom

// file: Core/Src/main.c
/* USER CODE BEGIN Header */
/**
  ******************************************************************************
  * @file           : main.c
  * @brief          : Main program body
  ******************************************************************************
  * @attention
  *
  * Copyright (c) 2026 STMicroelectronics.
  * All rights reserved.
  *
  * This software is licensed under terms that can be found in the LICENSE file
  * in the root directory of this software component.
  * If no LICENSE file comes with this software, it is provided AS-IS.
  *
  ******************************************************************************
  */
/* USER CODE END Header */
#include "main.h"
#include "cmsis_os.h"
#include "adc.h"
#include "dma.h"
#include "i2c.h"
#include "spi.h"
#include "tim.h"
#include "usart.h"
#include "gpio.h"

/* USER CODE BEGIN Includes */

#include "User_Task.h"

/* USER CODE END Includes */

void SystemClock_Config(void);
void MX_FREERTOS_Init(void);

int main(void)
{

  /* MCU Configuration--------------------------------------------------------*/

  /* Reset of all peripherals, Initializes the Flash interface and the Systick. */
  HAL_Init();

  /* Configure the system clock */
  SystemClock_Config();

  /* Initialize all configured peripherals */
  MX_GPIO_Init();
  MX_DMA_Init();
  MX_ADC1_Init();
  MX_TIM1_Init();
  MX_TIM3_Init();
  MX_TIM4_Init();
  MX_TIM8_Init();
  MX_TIM9_Init();
  MX_UART4_Init();
  MX_UART5_Init();
  MX_USART2_UART_Init();
  MX_USART3_UART_Init();
  MX_USART6_UART_Init();
  MX_I2C2_Init();
  MX_SPI2_Init();
  MX_TIM2_Init();
  MX_TIM10_Init();
  MX_TIM11_Init();
  MX_USART1_UART_Init();
  MX_ADC2_Init();
  MX_TIM5_Init();
  MX_TIM6_Init();
  MX_TIM12_Init();
  /* USER CODE BEGIN 2 */

  User_Init();			//Initialize all drivers and software

  /* USER CODE END 2 */

  /* Init scheduler */
  osKernelInitialize();  /* Call init function for freertos objects (in cmsis_os2.c) */
  MX_FREERTOS_Init();

  /* Start scheduler */
  osKernelStart();

  /* We should never get here as control is now taken by the scheduler */

  /* Infinite loop */
  while (1)
  {

  }
}

void SystemClock_Config(void)
{
  RCC_OscInitTypeDef RCC_OscInitStruct = {0};
  RCC_ClkInitTypeDef RCC_ClkInitStruct = {0};

  /** Configure the main internal regulator output voltage
  */
  __HAL_RCC_PWR_CLK_ENABLE();
  __HAL_PWR_VOLTAGESCALING_CONFIG(PWR_REGULATOR_VOLTAGE_SCALE1);

  /** Initializes the RCC Oscillators according to the specified parameters
  * in the RCC_OscInitTypeDef structure.
  */
  RCC_OscInitStruct.OscillatorType = RCC_OSCILLATORTYPE_HSE;
  RCC_OscInitStruct.HSEState = RCC_HSE_ON;
  RCC_OscInitStruct.PLL.PLLState = RCC_PLL_ON;
  RCC_OscInitStruct.PLL.PLLSource = RCC_PLLSOURCE_HSE;
  RCC_OscInitStruct.PLL.PLLM = 4;
  RCC_OscInitStruct.PLL.PLLN = 168;
  RCC_OscInitStruct.PLL.PLLP = RCC_PLLP_DIV2;
  RCC_OscInitStruct.PLL.PLLQ = 4;
  if (HAL_RCC_OscConfig(&RCC_OscInitStruct) != HAL_OK)
  {
    Error_Handler();
  }

  /** Initializes the CPU, AHB and APB buses clocks
  */
  RCC_ClkInitStruct.ClockType = RCC_CLOCKTYPE_HCLK|RCC_CLOCKTYPE_SYSCLK
                              |RCC_CLOCKTYPE_PCLK1|RCC_CLOCKTYPE_PCLK2;
  RCC_ClkInitStruct.SYSCLKSource = RCC_SYSCLKSOURCE_PLLCLK;
  RCC_ClkInitStruct.AHBCLKDivider = RCC_SYSCLK_DIV1;
  RCC_ClkInitStruct.APB1CLKDivider = RCC_HCLK_DIV4;
  RCC_ClkInitStruct.APB2CLKDivider = RCC_HCLK_DIV2;

  if (HAL_RCC_ClockConfig(&RCC_ClkInitStruct, FLASH_LATENCY_5) != HAL_OK)
  {
    Error_Handler();
  }
}

void HAL_TIM_PeriodElapsedCallback(TIM_HandleTypeDef *htim)
{
  if (htim->Instance == TIM7)
  {
    HAL_IncTick();
  }
}

void Error_Handler(void)
{
  __disable_irq();
  while (1)
  {
  }
}

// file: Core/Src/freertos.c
/* USER CODE BEGIN Header */
/**
  ******************************************************************************
  * File Name          : freertos.c
  * Description        : Code for freertos applications
  ******************************************************************************
  * @attention
  *
  * Copyright (c) 2026 STMicroelectronics.
  * All rights reserved.
  *
  * This software is licensed under terms that can be found in the LICENSE file
  * in the root directory of this software component.
  * If no LICENSE file comes with this software, it is provided AS-IS.
  *
  ******************************************************************************
  */
/* USER CODE END Header */

#include "FreeRTOS.h"
#include "task.h"
#include "main.h"
#include "cmsis_os.h"

/* USER CODE BEGIN Includes */

#include "User_Task.h"
#include "stm32f4xx_it.h"

/* USER CODE END Includes */

/* Definitions for defaultTask */
osThreadId_t defaultTaskHandle;
const osThreadAttr_t defaultTask_attributes = {
  .name = "defaultTask",
  .stack_size = 64 * 4,
  .priority = (osPriority_t) osPriorityNormal,
};
/* Definitions for RUN_LED_Flash */
osThreadId_t RUN_LED_FlashHandle;
const osThreadAttr_t RUN_LED_Flash_attributes = {
  .name = "RUN_LED_Flash",
  .stack_size = 64 * 4,
  .priority = (osPriority_t) osPriorityLow,
};
/* Definitions for State_LED_Flash */
osThreadId_t State_LED_FlashHandle;
const osThreadAttr_t State_LED_Flash_attributes = {
  .name = "State_LED_Flash",
  .stack_size = 64 * 4,
  .priority = (osPriority_t) osPriorityLow,
};
/* Definitions for KEY_Scan */
osThreadId_t KEY_ScanHandle;
const osThreadAttr_t KEY_Scan_attributes = {
  .name = "KEY_Scan",
  .stack_size = 64 * 4,
  .priority = (osPriority_t) osPriorityHigh,
};
/* Definitions for Set_And_Show */
osThreadId_t Set_And_ShowHandle;
const osThreadAttr_t Set_And_Show_attributes = {
  .name = "Set_And_Show",
  .stack_size = 512 * 4,
  .priority = (osPriority_t) osPriorityNormal,
};
/* Definitions for Slow_Compute */
osThreadId_t Slow_ComputeHandle;
const osThreadAttr_t Slow_Compute_attributes = {
  .name = "Slow_Compute",
  .stack_size = 512 * 4,
  .priority = (osPriority_t) osPriorityAboveNormal,
};
/* Definitions for UART_Debug */
osThreadId_t UART_DebugHandle;
const osThreadAttr_t UART_Debug_attributes = {
  .name = "UART_Debug",
  .stack_size = 512 * 4,
  .priority = (osPriority_t) osPriorityBelowNormal,
};
/* Definitions for High_Compute */
osThreadId_t High_ComputeHandle;
const osThreadAttr_t High_Compute_attributes = {
  .name = "High_Compute",
  .stack_size = 512 * 4,
  .priority = (osPriority_t) osPriorityAboveNormal,
};

void StartDefaultTask(void *argument);
void RUN_LED_Flash_Task(void *argument);
void State_LED_Flash_Task(void *argument);
void KEY_Scan_Task(void *argument);
void Set_And_Show_Task(void *argument);
void Slow_Compute_Task(void *argument);
void UART_Debug_Task(void *argument);
void High_Compute_Task(void *argument);

void MX_FREERTOS_Init(void); /* (MISRA C 2004 rule 8.1) */

void MX_FREERTOS_Init(void) {

  /* Create the thread(s) */
  /* creation of defaultTask */
  defaultTaskHandle = osThreadNew(StartDefaultTask, NULL, &defaultTask_attributes);

  /* creation of RUN_LED_Flash */
  RUN_LED_FlashHandle = osThreadNew(RUN_LED_Flash_Task, NULL, &RUN_LED_Flash_attributes);

  /* creation of State_LED_Flash */
  State_LED_FlashHandle = osThreadNew(State_LED_Flash_Task, NULL, &State_LED_Flash_attributes);

  /* creation of KEY_Scan */
  KEY_ScanHandle = osThreadNew(KEY_Scan_Task, NULL, &KEY_Scan_attributes);

  /* creation of Set_And_Show */
  Set_And_ShowHandle = osThreadNew(Set_And_Show_Task, NULL, &Set_And_Show_attributes);

  /* creation of Slow_Compute */
  Slow_ComputeHandle = osThreadNew(Slow_Compute_Task, NULL, &Slow_Compute_attributes);

  /* creation of UART_Debug */
  UART_DebugHandle = osThreadNew(UART_Debug_Task, NULL, &UART_Debug_attributes);

  /* creation of High_Compute */
  High_ComputeHandle = osThreadNew(High_Compute_Task, NULL, &High_Compute_attributes);

}

void StartDefaultTask(void *argument)
{
  for(;;)
  {
    osDelay(1);
  }
}

__weak void RUN_LED_Flash_Task(void *argument)
{
  for(;;)
  {
    osDelay(1);
  }
}

__weak void State_LED_Flash_Task(void *argument)
{
  for(;;)
  {
    osDelay(1);
  }
}

__weak void KEY_Scan_Task(void *argument)
{
  for(;;)
  {
    osDelay(1);
  }
}

__weak void Set_And_Show_Task(void *argument)
{
  for(;;)
  {
    osDelay(1);
  }
}

__weak void Slow_Compute_Task(void *argument)
{
  for(;;)
  {
    osDelay(1);
  }
}

__weak void UART_Debug_Task(void *argument)
{
  for(;;)
  {
    osDelay(1);
  }
}

__weak void High_Compute_Task(void *argument)
{
  for(;;)
  {
    osDelay(1);
  }
}
